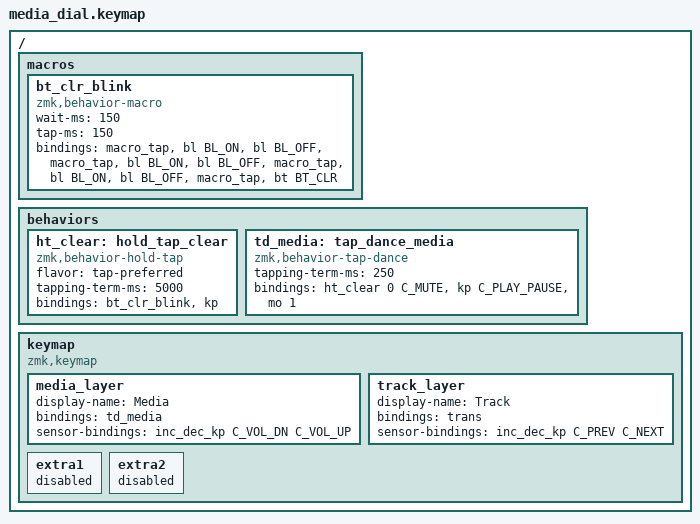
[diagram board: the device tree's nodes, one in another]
/*
 * SPDX-License-Identifier: MIT
 */

#include <behaviors.dtsi>
#include <dt-bindings/zmk/keys.h>
#include <dt-bindings/zmk/bt.h>
#include <dt-bindings/zmk/backlight.h>

/ {
    macros {
        // Chop den 3 cai roi xoa pairing cua profile dang dung,
        // de co the ghep lai voi may khac.
        bt_clr_blink: bt_clr_blink {
            compatible = "zmk,behavior-macro";
            #binding-cells = <0>;
            wait-ms = <150>;
            tap-ms = <150>;
            bindings
                = <&macro_tap &bl BL_ON &bl BL_OFF>
                , <&macro_tap &bl BL_ON &bl BL_OFF>
                , <&macro_tap &bl BL_ON &bl BL_OFF>
                , <&macro_tap &bt BT_CLR>
                ;
        };
    };

    behaviors {
        // Nha ra nhanh -> mute. Giu du 5 giay -> chop den va xoa pairing.
        // Tham so thu nhat (0) khong duoc dung, vi macro khong nhan tham so
        // nao ca, nhung hold-tap van doi phai truyen du hai tham so.
        ht_clear: hold_tap_clear {
            compatible = "zmk,behavior-hold-tap";
            #binding-cells = <2>;
            flavor = "tap-preferred";
            tapping-term-ms = <5000>;
            bindings = <&bt_clr_blink>, <&kp>;
        };

        //   1 nhan  : mute / unmute   (giu 5 giay = xoa pairing)
        //   2 nhan  : play / pause
        //   3 nhan  : giu lai lan thu 3 roi xoay = chuyen bai
        td_media: tap_dance_media {
            compatible = "zmk,behavior-tap-dance";
            #binding-cells = <0>;
            tapping-term-ms = <250>;
            bindings = <&ht_clear 0 C_MUTE>, <&kp C_PLAY_PAUSE>, <&mo 1>;
        };
    };

    keymap {
        compatible = "zmk,keymap";

        media_layer {
            display-name = "Media";
            bindings = <&td_media>;

            // Xoay trai: tang tieng -- Xoay phai: giam tieng
            sensor-bindings = <&inc_dec_kp C_VOL_DN C_VOL_UP>;
        };

        track_layer {
            display-name = "Track";
            bindings = <&trans>;

            // Nhan 3 lan, giu lan cuoi roi xoay: chuyen bai hat
            sensor-bindings = <&inc_dec_kp C_PREV C_NEXT>;
        };

        // Layer trong de danh cho ZMK Studio. Ban build thuong bo qua chung,
        // chi ban co Studio moi thay va cho phep dung toi.
        extra1 {
            status = "reserved";
        };

        extra2 {
            status = "reserved";
        };
    };
};
